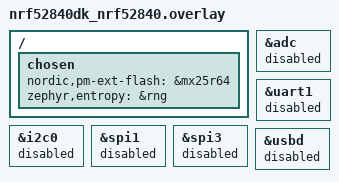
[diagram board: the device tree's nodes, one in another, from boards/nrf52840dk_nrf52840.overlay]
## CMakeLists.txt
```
#
# Copyright (c) 2024 Nordic Semiconductor ASA
#
# SPDX-License-Identifier: LicenseRef-Nordic-5-Clause
#

cmake_minimum_required(VERSION 3.20.0)

find_package(Zephyr HINTS $ENV{ZEPHYR_BASE})

project(matter-smoke-co-alarm)

# Enable GNU STD support and initialize the Matter Data Model.
include(${ZEPHYR_CONNECTEDHOMEIP_MODULE_DIR}/config/nrfconnect/app/enable-gnu-std.cmake)
include(${ZEPHYR_CONNECTEDHOMEIP_MODULE_DIR}/src/app/chip_data_model.cmake)

# NORDIC SDK APP START

# Include all source files that are located in the Matter common directory.
include(${ZEPHYR_NRF_MODULE_DIR}/samples/matter/common/cmake/source_common.cmake)

target_include_directories(app PRIVATE
    src
    ${CONFIG_NCS_SAMPLE_MATTER_ZAP_FILES_PATH}
)

target_sources(app PRIVATE
    src/app_task.cpp
    src/main.cpp
    src/zcl_callbacks.cpp
)

chip_configure_data_model(app
    INCLUDE_SERVER
    BYPASS_IDL
    GEN_DIR ${CONFIG_NCS_SAMPLE_MATTER_ZAP_FILES_PATH}/zap-generated
    ZAP_FILE ${CMAKE_CURRENT_SOURCE_DIR}/${CONFIG_NCS_SAMPLE_MATTER_ZAP_FILES_PATH}/smoke_co_alarm.zap
)
# NORDIC SDK APP END
```

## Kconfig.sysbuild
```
#
# Copyright (c) 2024 Nordic Semiconductor ASA
#
# SPDX-License-Identifier: LicenseRef-Nordic-5-Clause
#

#### Radio core selection
config NRF_DEFAULT_IPC_RADIO
	default y

# Enable IEEE802.15.4 serialization to network core
# This config automatically pulls in the `overlay-802154.conf` in the ipc_radio image
config NETCORE_IPC_RADIO_IEEE802154
	default y if SOC_SERIES_NRF53X

# Enable Bluetooth serialization to network core
# This config automatically pulls in the `overlay-bt_hci_ipc.conf` in the ipc_radio image
config NETCORE_IPC_RADIO_BT_HCI_IPC
	default y if SOC_SERIES_NRF53X

#### Bootloader
choice BOOTLOADER
	default BOOTLOADER_MCUBOOT
endchoice

if BOOTLOADER_MCUBOOT

#### DFU multi-image support
config DFU_MULTI_IMAGE_PACKAGE_BUILD
	default y

config DFU_MULTI_IMAGE_PACKAGE_APP
	default y

config PM_EXTERNAL_FLASH_MCUBOOT_SECONDARY
	default y

#### DFU network core configuration
if SOC_SERIES_NRF53X

config MCUBOOT_UPDATEABLE_IMAGES
	default 2

choice MCUBOOT_MODE
	default MCUBOOT_MODE_OVERWRITE_ONLY
endchoice

choice BOOT_SIGNATURE_TYPE
	default BOOT_SIGNATURE_TYPE_RSA
endchoice

config SECURE_BOOT_NETCORE
	default y

config NETCORE_APP_UPDATE
	default y

config DFU_MULTI_IMAGE_PACKAGE_NET
	default y

endif # SOC_SERIES_NRF53X

if BOARD_NRF54L15DK

# Disable checking the external drivers for nRF54L15 DKs.
config PM_OVERRIDE_EXTERNAL_DRIVER_CHECK
	default y

endif # BOARD_NRF54L15DK
endif # BOOTLOADER_MCUBOOT

#### Enable generating factory data
config MATTER_FACTORY_DATA_GENERATE
	default y

source "${ZEPHYR_BASE}/share/sysbuild/Kconfig"
```

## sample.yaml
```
sample:
  description: Matter Smoke CO Alarm example
  name: Matter Smoke CO Alarm
tests:
  sample.matter.smoke_co_alarm.debug:
    sysbuild: true
    build_only: true
    integration_platforms:
      - nrf52840dk/nrf52840
      - nrf5340dk/nrf5340/cpuapp
      - nrf54l15dk/nrf54l15/cpuapp
      - nrf54l15dk/nrf54l10/cpuapp
    platform_allow: nrf52840dk/nrf52840 nrf5340dk/nrf5340/cpuapp nrf54l15dk/nrf54l15/cpuapp
      nrf54l15dk/nrf54l10/cpuapp
    tags: sysbuild ci_samples_matter
  sample.matter.smoke_co_alarm.release:
    sysbuild: true
    build_only: true
    extra_args: FILE_SUFFIX=release
      SB_CONFIG_BOOTLOADER_MCUBOOT=y SB_CONFIG_PARTITION_MANAGER=y
    integration_platforms:
      - nrf52840dk/nrf52840
      - nrf5340dk/nrf5340/cpuapp
      - nrf54l15dk/nrf54l15/cpuapp
      - nrf54l15dk/nrf54l10/cpuapp
    platform_allow: nrf52840dk/nrf52840 nrf5340dk/nrf5340/cpuapp nrf54l15dk/nrf54l15/cpuapp
      nrf54l15dk/nrf54l10/cpuapp
    tags: sysbuild ci_samples_matter
  sample.matter.smoke_co_alarm.lto:
    sysbuild: true
    build_only: true
    extra_args: CONFIG_LTO=y CONFIG_ISR_TABLES_LOCAL_DECLARATION=y
    integration_platforms:
      - nrf52840dk/nrf52840
      - nrf5340dk/nrf5340/cpuapp
      - nrf54l15dk/nrf54l15/cpuapp
      - nrf54l15dk/nrf54l10/cpuapp
    platform_allow: nrf52840dk/nrf52840 nrf5340dk/nrf5340/cpuapp nrf54l15dk/nrf54l15/cpuapp
      nrf54l15dk/nrf54l10/cpuapp
    tags: sysbuild ci_samples_matter
  sample.matter.smoke_co_alarm.release.nrf54l15.power_consumption:
    sysbuild: true
    build_only: true
    extra_args: FILE_SUFFIX=release CONFIG_NCS_SAMPLE_MATTER_LEDS=n
      CONFIG_NCS_SAMPLE_MATTER_WATCHDOG=n
    integration_platforms:
      - nrf54l15dk/nrf54l15/cpuapp
      - nrf54l15dk/nrf54l10/cpuapp
    platform_allow: nrf54l15dk/nrf54l15/cpuapp nrf54l15dk/nrf54l10/cpuapp
    tags: sysbuild ci_samples_matter
  sample.matter.smoke_co_alarm.debug.reference:
    sysbuild: true
    build_only: true
    integration_platforms:
      - nrf54l15dk/nrf54l15/cpuapp
    extra_args: smoke_co_alarm_SNIPPET="diagnostic-logs"
    platform_allow: nrf54l15dk/nrf54l15/cpuapp
    tags: sysbuild ci_samples_matter
```

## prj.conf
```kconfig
#
# Copyright (c) 2024 Nordic Semiconductor ASA
#
# SPDX-License-Identifier: LicenseRef-Nordic-5-Clause
#

# Enable CHIP
CONFIG_CHIP=y
CONFIG_CHIP_PROJECT_CONFIG="src/chip_project_config.h"
# 32768 == 0x8000 (example Product ID added temporaly,
# as there is no assigned PID on the following list:
# https://github.com/project-chip/connectedhomeip/blob/482e6fd03196a6de45465a90003947ef4b86e0b1/docs/examples/discussion/PID_allocation_for_example_apps.md)
CONFIG_CHIP_DEVICE_PRODUCT_ID=32768
CONFIG_STD_CPP17=y

# Enable Matter pairing automatically on application start.
CONFIG_CHIP_ENABLE_PAIRING_AUTOSTART=y

# Enable Matter extended announcement and increase duration to 1 hour.
CONFIG_CHIP_BLE_EXT_ADVERTISING=y
CONFIG_CHIP_BLE_ADVERTISING_DURATION=60

# Add support for LEDs and buttons on Nordic development kits
CONFIG_DK_LIBRARY=y

# Bluetooth Low Energy configuration
CONFIG_BT_DEVICE_NAME="MatterSmoke"

# Suspend devices when the CPU goes into sleep
CONFIG_PM_DEVICE=y

# Other settings
CONFIG_THREAD_NAME=y
CONFIG_MPU_STACK_GUARD=y
CONFIG_RESET_ON_FATAL_ERROR=n
CONFIG_CHIP_LIB_SHELL=y

# Reduce application size
CONFIG_USE_SEGGER_RTT=n

# Enable Factory Data feature
CONFIG_CHIP_FACTORY_DATA=y
CONFIG_CHIP_FACTORY_DATA_BUILD=y
```

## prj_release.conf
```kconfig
#
# Copyright (c) 2024 Nordic Semiconductor ASA
#
# SPDX-License-Identifier: LicenseRef-Nordic-5-Clause
#

# Enable CHIP
CONFIG_CHIP=y
CONFIG_CHIP_PROJECT_CONFIG="src/chip_project_config.h"
# 32768 == 0x8000 (example Product ID added temporaly,
# as there is no assigned PID on the following list:
# https://github.com/project-chip/connectedhomeip/blob/482e6fd03196a6de45465a90003947ef4b86e0b1/docs/examples/discussion/PID_allocation_for_example_apps.md)
CONFIG_CHIP_DEVICE_PRODUCT_ID=32768
CONFIG_STD_CPP17=y

# Enable Matter pairing automatically on application start.
CONFIG_CHIP_ENABLE_PAIRING_AUTOSTART=y

# Enable Matter extended announcement and increase duration to 1 hour.
CONFIG_CHIP_BLE_EXT_ADVERTISING=y
CONFIG_CHIP_BLE_ADVERTISING_DURATION=60

# Add support for LEDs and buttons on Nordic development kits
CONFIG_DK_LIBRARY=y

# Try to disable unused RAM blocks to reduce power consumption
CONFIG_RAM_POWER_DOWN_LIBRARY=y

# Bluetooth Low Energy configuration
CONFIG_BT_DEVICE_NAME="MatterSmoke"

# Suspend devices when the CPU goes into sleep
CONFIG_PM_DEVICE=y

# Enable system reset on fatal error
CONFIG_RESET_ON_FATAL_ERROR=y

# Disable all debug features
CONFIG_USE_SEGGER_RTT=n
CONFIG_SHELL=n
CONFIG_OPENTHREAD_SHELL=n
CONFIG_CONSOLE=n
CONFIG_UART_CONSOLE=n
CONFIG_SERIAL=n
CONFIG_LOG=n
CONFIG_LOG_MODE_MINIMAL=n
CONFIG_ASSERT_VERBOSE=n
CONFIG_ASSERT_NO_FILE_INFO=y
CONFIG_PRINTK=n
CONFIG_PRINTK_SYNC=n
CONFIG_THREAD_NAME=n
CONFIG_BOOT_BANNER=n

# Enable Factory Data feature
CONFIG_CHIP_FACTORY_DATA=y
CONFIG_CHIP_FACTORY_DATA_BUILD=y

# Enable Watchdog
CONFIG_NCS_SAMPLE_MATTER_WATCHDOG=y
```

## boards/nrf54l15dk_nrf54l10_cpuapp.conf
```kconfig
#
# Copyright (c) 2024 Nordic Semiconductor ASA
#
# SPDX-License-Identifier: LicenseRef-Nordic-5-Clause
#

# Multirole is the only currently supported role by SoftDevice.
CONFIG_BT_LL_SOFTDEVICE_MULTIROLE=y

# nRF54L15 requires bigger stack sizes than nRF52/nRF53 families
CONFIG_CHIP_MALLOC_SYS_HEAP_SIZE=10240
CONFIG_MPSL_WORK_STACK_SIZE=2048

# Set the ZMS sector count to match the settings partition size that is 40 kB for this application.
CONFIG_SETTINGS_ZMS_SECTOR_COUNT=10
# Workaround required as Zephyr L2 implies usage of NVS backend for settings.
# It should be removed once the proper fix will be applied in Zephyr.
CONFIG_NVS=n

# Low Power mode
CONFIG_POWEROFF=y

# Disabling of unused RAM blocks to reduce power consumption is not yet available for nRF54L10 SoC
CONFIG_RAM_POWER_DOWN_LIBRARY=n
```

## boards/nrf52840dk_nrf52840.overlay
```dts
/*
 * Copyright (c) 2024 Nordic Semiconductor ASA
 *
 * SPDX-License-Identifier: LicenseRef-Nordic-5-Clause
 */

/ {
	chosen {
		nordic,pm-ext-flash = &mx25r64;
	};

	/*
	* In some default configurations within the nRF Connect SDK,
	* e.g. on nRF52840, the chosen zephyr,entropy node is &cryptocell.
	* This devicetree overlay ensures that default is overridden wherever it
	* is set, as this application uses the RNG node for entropy exclusively.
	*/
	chosen {
		zephyr,entropy = &rng;
	};
};

/* Disable unused peripherals to reduce power consumption */
&adc {
	status = "disabled";
};
&uart1 {
	status = "disabled";
};
&i2c0 {
	status = "disabled";
};
&spi1 {
	status = "disabled";
};
&spi3 {
	status = "disabled";
};
&usbd {
	status = "disabled";
};
```

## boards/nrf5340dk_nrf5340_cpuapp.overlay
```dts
/*
 * Copyright (c) 2024 Nordic Semiconductor ASA
 *
 * SPDX-License-Identifier: LicenseRef-Nordic-5-Clause
 */

#include <zephyr/dt-bindings/ipc_service/static_vrings.h>

/ {
	chosen {
		nordic,pm-ext-flash = &mx25r64;
	};
};

/* Set IPC thread priority to the highest value to not collide with other threads. */
&ipc0 {
    zephyr,priority = <0 PRIO_COOP>;
};

/* Disable unused peripherals to reduce power consumption */
&adc {
	status = "disabled";
};
&i2c1 {
	status = "disabled";
};
&spi2 {
	status = "disabled";
};
&usbd {
	status = "disabled";
};
```

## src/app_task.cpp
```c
/*
 * Copyright (c) 2024 Nordic Semiconductor ASA
 *
 * SPDX-License-Identifier: LicenseRef-Nordic-5-Clause
 */

#include "app_task.h"

#include "app/matter_init.h"
#include "app/task_executor.h"
#include "board/board.h"
#include "lib/core/CHIPError.h"
#include "lib/support/CodeUtils.h"

#ifdef CONFIG_CHIP_OTA_REQUESTOR
#include "dfu/ota/ota_util.h"
#endif

#include <app-common/zap-generated/attributes/Accessors.h>
#include <app/clusters/identify-server/identify-server.h>
#include <app/clusters/smoke-co-alarm-server/SmokeCOTestEventTriggerHandler.h>
#include <app/clusters/smoke-co-alarm-server/smoke-co-alarm-server.h>
#include <app/server/OnboardingCodesUtil.h>

#include <zephyr/logging/log.h>

LOG_MODULE_DECLARE(app, CONFIG_CHIP_APP_LOG_LEVEL);

using namespace ::chip;
using namespace ::chip::app;
using namespace ::chip::DeviceLayer;

namespace
{

constexpr uint32_t kExpressedStateLedEvenBlinkMs = 300;
constexpr uint32_t kExpressedStateLedOddBlink1Ms = 300;
constexpr uint32_t kExpressedStateLedOddBlink2Ms = 700;
constexpr uint32_t kSelfTestDurationMs = 5000;
constexpr uint32_t kSelfTestLedUpdateTimeMs = 200;

static std::array<Clusters::SmokeCoAlarm::ExpressedStateEnum, SmokeCoAlarmServer::kPriorityOrderLength>
	sPriorityOrder = { Clusters::SmokeCoAlarm::ExpressedStateEnum::kSmokeAlarm,
			   Clusters::SmokeCoAlarm::ExpressedStateEnum::kCOAlarm,
			   Clusters::SmokeCoAlarm::ExpressedStateEnum::kHardwareFault,
			   Clusters::SmokeCoAlarm::ExpressedStateEnum::kTesting,
			   Clusters::SmokeCoAlarm::ExpressedStateEnum::kEndOfService,
			   Clusters::SmokeCoAlarm::ExpressedStateEnum::kBatteryAlert,
			   Clusters::SmokeCoAlarm::ExpressedStateEnum::kInterconnectSmoke,
			   Clusters::SmokeCoAlarm::ExpressedStateEnum::kInterconnectCO };

Identify sIdentify = { AppTask::Instance().kSmokeCoAlarmEndpointId, AppTask::IdentifyStartHandler,
		       AppTask::IdentifyStopHandler, Clusters::Identify::IdentifyTypeEnum::kVisibleIndicator };

#ifdef CONFIG_CHIP_ICD_UAT_SUPPORT
#define UAT_BUTTON_MASK DK_BTN3_MSK
#endif
} /* namespace */

void AppTask::IdentifyStartHandler(Identify *)
{
	Nrf::PostTask(
		[] { Nrf::GetBoard().GetLED(Nrf::DeviceLeds::LED2).Blink(Nrf::LedConsts::kIdentifyBlinkRate_ms); });
}

void AppTask::IdentifyStopHandler(Identify *)
{
	Nrf::PostTask([] { Nrf::GetBoard().GetLED(Nrf::DeviceLeds::LED2).Set(false); });
}

void AppTask::ButtonEventHandler(Nrf::ButtonState state, Nrf::ButtonMask hasChanged)
{
#ifdef CONFIG_CHIP_ICD_UAT_SUPPORT
	if ((UAT_BUTTON_MASK & state & hasChanged)) {
		LOG_INF("ICD UserActiveMode has been triggered.");
		Server::GetInstance().GetICDManager().OnNetworkActivity();
	}
#endif
}

void AppTask::UpdatedExpressedLedState()
{
	Clusters::SmokeCoAlarm::ExpressedStateEnum state;
	SmokeCoAlarmServer::Instance().GetExpressedState(kSmokeCoAlarmEndpointId, state);

	if (mCurrentState == state) {
		return;
	}
	mCurrentState = state;

	k_timer_stop(&mSelfTestLedTimer);

	switch (state) {
	case Clusters::SmokeCoAlarm::ExpressedStateEnum::kNormal:
		Nrf::GetBoard().GetLED(Nrf::DeviceLeds::LED2).Set(false);
		Nrf::GetBoard().GetLED(Nrf::DeviceLeds::LED3).Set(false);
		Nrf::GetBoard().GetLED(Nrf::DeviceLeds::LED4).Set(false);
		break;
	case Clusters::SmokeCoAlarm::ExpressedStateEnum::kSmokeAlarm:
		Nrf::GetBoard().GetLED(Nrf::DeviceLeds::LED2).Blink(kExpressedStateLedEvenBlinkMs);
		Nrf::GetBoard().GetLED(Nrf::DeviceLeds::LED3).Set(false);
		Nrf::GetBoard().GetLED(Nrf::DeviceLeds::LED4).Set(false);
		break;
	case Clusters::SmokeCoAlarm::ExpressedStateEnum::kCOAlarm:
		Nrf::GetBoard().GetLED(Nrf::DeviceLeds::LED2).Set(false);
		Nrf::GetBoard().GetLED(Nrf::DeviceLeds::LED3).Blink(kExpressedStateLedEvenBlinkMs);
		Nrf::GetBoard().GetLED(Nrf::DeviceLeds::LED4).Set(false);
		break;
	case Clusters::SmokeCoAlarm::ExpressedStateEnum::kBatteryAlert:
		Nrf::GetBoard().GetLED(Nrf::DeviceLeds::LED2).Set(false);
		Nrf::GetBoard().GetLED(Nrf::DeviceLeds::LED3).Set(false);
		Nrf::GetBoard().GetLED(Nrf::DeviceLeds::LED4).Blink(kExpressedStateLedEvenBlinkMs);
		break;
	case Clusters::SmokeCoAlarm::ExpressedStateEnum::kTesting:
		Nrf::GetBoard().GetLED(Nrf::DeviceLeds::LED2).Set(false);
		Nrf::GetBoard().GetLED(Nrf::DeviceLeds::LED3).Set(false);
		Nrf::GetBoard().GetLED(Nrf::DeviceLeds::LED4).Set(false);

		k_timer_start(&mSelfTestLedTimer, K_MSEC(kSelfTestLedUpdateTimeMs), K_NO_WAIT);
		Nrf::GetBoard().GetLED(Nrf::DeviceLeds::LED2).Set(true);

		break;
	case Clusters::SmokeCoAlarm::ExpressedStateEnum::kHardwareFault:
		Nrf::GetBoard().GetLED(Nrf::DeviceLeds::LED2).Set(false);
		Nrf::GetBoard().GetLED(Nrf::DeviceLeds::LED3).Set(false);
		Nrf::GetBoard().GetLED(Nrf::DeviceLeds::LED4).Set(false);

		Nrf::GetBoard()
			.GetLED(Nrf::DeviceLeds::LED2)
			.Blink(kExpressedStateLedOddBlink1Ms, kExpressedStateLedOddBlink2Ms);
		Nrf::GetBoard()
			.GetLED(Nrf::DeviceLeds::LED3)
			.Blink(kExpressedStateLedOddBlink1Ms, kExpressedStateLedOddBlink2Ms);
		Nrf::GetBoard()
			.GetLED(Nrf::DeviceLeds::LED4)
			.Blink(kExpressedStateLedOddBlink1Ms, kExpressedStateLedOddBlink2Ms);
		break;
	case Clusters::SmokeCoAlarm::ExpressedStateEnum::kEndOfService:
		Nrf::GetBoard().GetLED(Nrf::DeviceLeds::LED2).Set(false);
		Nrf::GetBoard().GetLED(Nrf::DeviceLeds::LED3).Set(false);
		Nrf::GetBoard().GetLED(Nrf::DeviceLeds::LED4).Set(false);

		Nrf::GetBoard()
			.GetLED(Nrf::DeviceLeds::LED2)
			.Blink(kExpressedStateLedOddBlink2Ms, kExpressedStateLedOddBlink1Ms);
		Nrf::GetBoard()
			.GetLED(Nrf::DeviceLeds::LED3)
			.Blink(kExpressedStateLedOddBlink2Ms, kExpressedStateLedOddBlink1Ms);
		Nrf::GetBoard()
			.GetLED(Nrf::DeviceLeds::LED4)
			.Blink(kExpressedStateLedOddBlink2Ms, kExpressedStateLedOddBlink1Ms);
		break;
	case Clusters::SmokeCoAlarm::ExpressedStateEnum::kInterconnectSmoke:
	case Clusters::SmokeCoAlarm::ExpressedStateEnum::kInterconnectCO:
	case Clusters::SmokeCoAlarm::ExpressedStateEnum::kUnknownEnumValue:
	default:
		break;
	}
}

bool HandleSmokeCOTestEventTrigger(uint64_t eventTrigger)
{
	SmokeCOTrigger trigger = static_cast<SmokeCOTrigger>(eventTrigger);

	switch (trigger) {
	case SmokeCOTrigger::kForceSmokeCritical:
		LOG_INF("Triggered smoke alarm with critical severity");
		VerifyOrReturnValue(
			SmokeCoAlarmServer::Instance().SetSmokeState(AppTask::Instance().kSmokeCoAlarmEndpointId,
								     Clusters::SmokeCoAlarm::AlarmStateEnum::kCritical),
			false);
		SmokeCoAlarmServer::Instance().SetExpressedStateByPriority(AppTask::Instance().kSmokeCoAlarmEndpointId,
									   sPriorityOrder);
		break;
	case SmokeCOTrigger::kForceCOCritical:
		LOG_INF("Triggered CO alarm with critical severity");
		VerifyOrReturnValue(
			SmokeCoAlarmServer::Instance().SetCOState(AppTask::Instance().kSmokeCoAlarmEndpointId,
								  Clusters::SmokeCoAlarm::AlarmStateEnum::kCritical),
			false);
		SmokeCoAlarmServer::Instance().SetExpressedStateByPriority(AppTask::Instance().kSmokeCoAlarmEndpointId,
									   sPriorityOrder);
		break;
	case SmokeCOTrigger::kForceMalfunction:
		LOG_INF("Triggered hardware fault alert");
		VerifyOrReturnValue(SmokeCoAlarmServer::Instance().SetHardwareFaultAlert(
					    AppTask::Instance().kSmokeCoAlarmEndpointId, true),
				    false);
		SmokeCoAlarmServer::Instance().SetExpressedStateByPriority(AppTask::Instance().kSmokeCoAlarmEndpointId,
									   sPriorityOrder);
		break;
	case SmokeCOTrigger::kForceLowBatteryCritical:
		LOG_INF("Triggered low battery alert with critical severity");
		VerifyOrReturnValue(SmokeCoAlarmServer::Instance().SetBatteryAlert(
					    AppTask::Instance().kSmokeCoAlarmEndpointId,
					    Clusters::SmokeCoAlarm::AlarmStateEnum::kCritical),
				    false);
		SmokeCoAlarmServer::Instance().SetExpressedStateByPriority(AppTask::Instance().kSmokeCoAlarmEndpointId,
									   sPriorityOrder);
		break;
	case SmokeCOTrigger::kForceEndOfLife:
		LOG_INF("Triggered end of service alert");
		VerifyOrReturnValue(SmokeCoAlarmServer::Instance().SetEndOfServiceAlert(
					    AppTask::Instance().kSmokeCoAlarmEndpointId,
					    Clusters::SmokeCoAlarm::EndOfServiceEnum::kExpired),
				    false);
		SmokeCoAlarmServer::Instance().SetExpressedStateByPriority(AppTask::Instance().kSmokeCoAlarmEndpointId,
									   sPriorityOrder);
		break;
	case SmokeCOTrigger::kClearSmoke:
		LOG_INF("Triggered end of smoke alarm action");
		VerifyOrReturnValue(
			SmokeCoAlarmServer::Instance().SetSmokeState(AppTask::Instance().kSmokeCoAlarmEndpointId,
								     Clusters::SmokeCoAlarm::AlarmStateEnum::kNormal),
			false);
		SmokeCoAlarmServer::Instance().SetExpressedStateByPriority(AppTask::Instance().kSmokeCoAlarmEndpointId,
									   sPriorityOrder);
		break;
	case SmokeCOTrigger::kClearCO:
		LOG_INF("Triggered end of CO alarm action");
		VerifyOrReturnValue(
			SmokeCoAlarmServer::Instance().SetCOState(AppTask::Instance().kSmokeCoAlarmEndpointId,
								  Clusters::SmokeCoAlarm::AlarmStateEnum::kNormal),
			false);
		SmokeCoAlarmServer::Instance().SetExpressedStateByPriority(AppTask::Instance().kSmokeCoAlarmEndpointId,
									   sPriorityOrder);
		break;
	case SmokeCOTrigger::kClearMalfunction:
		LOG_INF("Triggered end of hardware fault alert action");
		VerifyOrReturnValue(SmokeCoAlarmServer::Instance().SetHardwareFaultAlert(
					    AppTask::Instance().kSmokeCoAlarmEndpointId, false),
				    false);
		SmokeCoAlarmServer::Instance().SetExpressedStateByPriority(AppTask::Instance().kSmokeCoAlarmEndpointId,
									   sPriorityOrder);
		break;
	case SmokeCOTrigger::kClearEndOfLife:
		LOG_INF("Triggered end of end of service alert action");
		VerifyOrReturnValue(SmokeCoAlarmServer::Instance().SetEndOfServiceAlert(
					    AppTask::Instance().kSmokeCoAlarmEndpointId,
					    Clusters::SmokeCoAlarm::EndOfServiceEnum::kNormal),
				    false);
		SmokeCoAlarmServer::Instance().SetExpressedStateByPriority(AppTask::Instance().kSmokeCoAlarmEndpointId,
									   sPriorityOrder);
		break;
	case SmokeCOTrigger::kClearBatteryLevelLow:
		LOG_INF("Triggered end of low battery level alert action");
		VerifyOrReturnValue(
			SmokeCoAlarmServer::Instance().SetBatteryAlert(AppTask::Instance().kSmokeCoAlarmEndpointId,
								       Clusters::SmokeCoAlarm::AlarmStateEnum::kNormal),
			false);
		SmokeCoAlarmServer::Instance().SetExpressedStateByPriority(AppTask::Instance().kSmokeCoAlarmEndpointId,
									   sPriorityOrder);
		break;
	case SmokeCOTrigger::kForceSmokeWarning:
		LOG_WRN("Triggered unsupported smoke alarm with warning severity");
		return false;
	case SmokeCOTrigger::kForceSmokeInterconnect:
		LOG_WRN("Triggered unsupported smoke interconnect alarm");
		return false;
	case SmokeCOTrigger::kForceCOWarning:
		LOG_WRN("Triggered unsupported CO alarm with warning severity");
		return false;
	case SmokeCOTrigger::kForceCOInterconnect:
		LOG_WRN("Triggered unsupported CO interconnect alarm");
		return false;
	case SmokeCOTrigger::kForceSmokeContaminationHigh:
		LOG_WRN("Triggered unsupported high smoke contamination alarm");
		return false;
	case SmokeCOTrigger::kForceSmokeContaminationLow:
		LOG_WRN("Triggered unsupported low smoke contamination alarm");
		return false;
	case SmokeCOTrigger::kForceSmokeSensitivityHigh:
		LOG_WRN("Triggered unsupported high smoke sensitivity alarm");
		return false;
	case SmokeCOTrigger::kForceSmokeSensitivityLow:
		LOG_WRN("Triggered unsupported low smoke sensitivity alarm");
		return false;
	case SmokeCOTrigger::kForceLowBatteryWarning:
		LOG_WRN("Triggered unsupported low battery alert with warning severity");
		return false;
	case SmokeCOTrigger::kForceSilence:
		LOG_WRN("Triggered unsupported alarm mute action");
		return false;
	case SmokeCOTrigger::kClearSmokeInterconnect:
		LOG_WRN("Triggered unsupported end of smoke interconnect alarm action");
		return false;
	case SmokeCOTrigger::kClearCOInterconnect:
		LOG_WRN("Triggered unsupported end of CO interconnect alarm action");
		return false;
	case SmokeCOTrigger::kClearSilence:
		LOG_WRN("Triggered unsupported unmute action");
		return false;
	case SmokeCOTrigger::kClearContamination:
		LOG_WRN("Triggered unsupported end of smoke contamination alert action");
		return false;
	case SmokeCOTrigger::kClearSensitivity:
		LOG_WRN("Triggered unsupported end of smoke sensitivity alert action");
		return false;
	default:
		return false;
	}

	AppTask::Instance().UpdatedExpressedLedState();

	return true;
}

void AppTask::SelfTestTimerTimeoutCallback(k_timer *timer)
{
	Nrf::PostTask([] { EndSelfTestEventHandler(); });
}

void AppTask::EndSelfTestEventHandler()
{
	LOG_INF("Alarm self test action end");
	SmokeCoAlarmServer::Instance().SetTestInProgress(kSmokeCoAlarmEndpointId, false);
	SmokeCoAlarmServer::Instance().SetExpressedStateByPriority(kSmokeCoAlarmEndpointId, sPriorityOrder);
	Instance().UpdatedExpressedLedState();
}

void AppTask::SelfTestLedTimerTimeoutCallback(k_timer *timer)
{
	Nrf::PostTask([] { SelfTestLedTimerEventHandler(); });
}

void AppTask::SelfTestLedTimerEventHandler()
{
	if (Nrf::GetBoard().GetLED(Nrf::DeviceLeds::LED2).GetState()) {
		Nrf::GetBoard().GetLED(Nrf::DeviceLeds::LED2).Set(false);
		Nrf::GetBoard().GetLED(Nrf::DeviceLeds::LED3).Set(true);
	} else if (Nrf::GetBoard().GetLED(Nrf::DeviceLeds::LED3).GetState()) {
		Nrf::GetBoard().GetLED(Nrf::DeviceLeds::LED3).Set(false);
		Nrf::GetBoard().GetLED(Nrf::DeviceLeds::LED4).Set(true);
	} else if (Nrf::GetBoard().GetLED(Nrf::DeviceLeds::LED4).GetState()) {
		Nrf::GetBoard().GetLED(Nrf::DeviceLeds::LED4).Set(false);
		Nrf::GetBoard().GetLED(Nrf::DeviceLeds::LED2).Set(true);
	}

	k_timer_start(&Instance().mSelfTestLedTimer, K_MSEC(kSelfTestLedUpdateTimeMs), K_NO_WAIT);
}

#ifdef CONFIG_NCS_SAMPLE_MATTER_TEST_EVENT_TRIGGERS
CHIP_ERROR AppTask::PowerSourceOnEventCallback(Nrf::Matter::TestEventTrigger::TriggerValue endpointId)
{
	if (endpointId == kWiredPowerSourceEndpointId || endpointId == kBatteryPowerSourceEndpointId) {
		LOG_INF("Event Trigger: Power Source on endpoint id %d activated.", endpointId);
	} else {
		LOG_ERR("Event Trigger: Power Source On triggered on invalid endpoint id %d", endpointId);
		return CHIP_ERROR_INVALID_ARGUMENT;
	}

	/* Wired power source is treated as primary one. */
	if (endpointId == kWiredPowerSourceEndpointId) {
		Clusters::PowerSource::Attributes::Status::Set(kWiredPowerSourceEndpointId,
							       Clusters::PowerSource::PowerSourceStatusEnum::kActive);

		Clusters::PowerSource::PowerSourceStatusEnum status;
		Clusters::PowerSource::Attributes::Status::Get(kBatteryPowerSourceEndpointId, &status);

		/* If battery power source was active, change its state to standby. */
		if (status == Clusters::PowerSource::PowerSourceStatusEnum::kActive) {
			Clusters::PowerSource::Attributes::Status::Set(
				kBatteryPowerSourceEndpointId, Clusters::PowerSource::PowerSourceStatusEnum::kStandby);
		}
	} else {
		Clusters::PowerSource::PowerSourceStatusEnum status;
		Clusters::PowerSource::Attributes::Status::Get(kWiredPowerSourceEndpointId, &status);

		/* If wired power source is active, change put requested power source into standby state to standby. */
		if (status == Clusters::PowerSource::PowerSourceStatusEnum::kActive) {
			Clusters::PowerSource::Attributes::Status::Set(
				kBatteryPowerSourceEndpointId, Clusters::PowerSource::PowerSourceStatusEnum::kStandby);
		} else {
			Clusters::PowerSource::Attributes::Status::Set(
				kBatteryPowerSourceEndpointId, Clusters::PowerSource::PowerSourceStatusEnum::kActive);
		}
	}

	return CHIP_NO_ERROR;
}

CHIP_ERROR AppTask::PowerSourceOffEventCallback(Nrf::Matter::TestEventTrigger::TriggerValue endpointId)
{
	if (endpointId == kWiredPowerSourceEndpointId || endpointId == kBatteryPowerSourceEndpointId) {
		LOG_INF("Event Trigger: Power Source on endpoint id %d deactivated.", endpointId);
	} else {
		LOG_ERR("Event Trigger: Power Source Off triggered on invalid endpoint id %d", endpointId);
		return CHIP_ERROR_INVALID_ARGUMENT;
	}

	/* Wired power source is treated as primary one. */
	if (endpointId == kWiredPowerSourceEndpointId) {
		Clusters::PowerSource::Attributes::Status::Set(
			kWiredPowerSourceEndpointId, Clusters::PowerSource::PowerSourceStatusEnum::kUnavailable);

		Clusters::PowerSource::PowerSourceStatusEnum status;
		Clusters::PowerSource::Attributes::Status::Get(kBatteryPowerSourceEndpointId, &status);

		/* If battery power source was standby, change its state to active. */
		if (status == Clusters::PowerSource::PowerSourceStatusEnum::kStandby) {
			Clusters::PowerSource::Attributes::Status::Set(
				kBatteryPowerSourceEndpointId, Clusters::PowerSource::PowerSourceStatusEnum::kActive);
		}
	} else {
		Clusters::PowerSource::Attributes::Status::Set(
			kBatteryPowerSourceEndpointId, Clusters::PowerSource::PowerSourceStatusEnum::kUnavailable);
	}

	return CHIP_NO_ERROR;
}
#endif

CHIP_ERROR AppTask::Init()
{
	/* Initialize Matter stack */
	ReturnErrorOnFailure(Nrf::Matter::PrepareServer());

	if (!Nrf::GetBoard().Init(ButtonEventHandler)) {
		LOG_ERR("User interface initialization failed.");
		return CHIP_ERROR_INCORRECT_STATE;
	}

	k_timer_init(&mSelfTestLedTimer, &SelfTestLedTimerTimeoutCallback, nullptr);
	k_timer_init(&mSelfTestTimer, &SelfTestTimerTimeoutCallback, nullptr);

	/* Register Matter event handler that controls the connectivity status LED based on the captured Matter network
	 * state. */
	ReturnErrorOnFailure(Nrf::Matter::RegisterEventHandler(Nrf::Board::DefaultMatterEventHandler, 0));

	/* Register Smoke CO Alarm test event triggers */
#ifdef CONFIG_NCS_SAMPLE_MATTER_TEST_EVENT_TRIGGERS
	/* Register Smoke CO alarm test events handler */
	static chip::SmokeCOTestEventTriggerHandler sSmokeCoAlarmTestEventTrigger;
	ReturnErrorOnFailure(Nrf::Matter::TestEventTrigger::Instance().RegisterTestEventTriggerHandler(
		&sSmokeCoAlarmTestEventTrigger));

	/* Register test event handler to change the power source. */
	ReturnErrorOnFailure(Nrf::Matter::TestEventTrigger::Instance().RegisterTestEventTrigger(
		kPowerSourceOnEventTriggerId,
		Nrf::Matter::TestEventTrigger::EventTrigger{ 0xFFFF, PowerSourceOnEventCallback }));
	ReturnErrorOnFailure(Nrf::Matter::TestEventTrigger::Instance().RegisterTestEventTrigger(
		kPowerSourceOffEventTriggerId,
		Nrf::Matter::TestEventTrigger::EventTrigger{ 0xFFFF, PowerSourceOffEventCallback }));
#endif

	return Nrf::Matter::StartServer();
}

CHIP_ERROR AppTask::StartApp()
{
	ReturnErrorOnFailure(Init());

	while (true) {
		Nrf::DispatchNextTask();
	}

	return CHIP_NO_ERROR;
}

void AppTask::SelfTestHandler()
{
	LOG_INF("Triggered alarm self test action");
	k_timer_start(&Instance().mSelfTestTimer, K_MSEC(kSelfTestDurationMs), K_NO_WAIT);
	UpdatedExpressedLedState();
}
```
